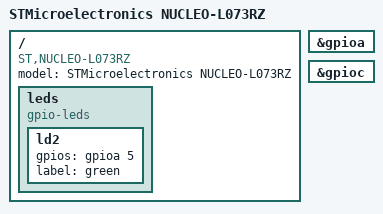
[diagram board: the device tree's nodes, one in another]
/**
 * \file
 * \brief Devicetree for NUCLEO-L073RZ
 *
 * \author Copyright (C) 2017 Kamil Szczygiel http://www.distortec.com http://www.freddiechopin.info
 *
 * \par License
 * This Source Code Form is subject to the terms of the Mozilla Public License, v. 2.0. If a copy of the MPL was not
 * distributed with this file, You can obtain one at http://mozilla.org/MPL/2.0/.
 */

/dts-v1/;

#include "STM32L073RZ.dtsi"

/ {
	compatible = "ST,NUCLEO-L073RZ", "ST,STM32L073RZ";
	model = "STMicroelectronics NUCLEO-L073RZ";

	leds {
		compatible = "gpio-leds";
		status = "okay";

		ld2 {
			gpios = <&gpioa 5 0>;
			label = "green";
			status = "okay";
		};
	};
};

&gpioa {
	status = "okay";
};

&gpioc {
	status = "okay";
};
